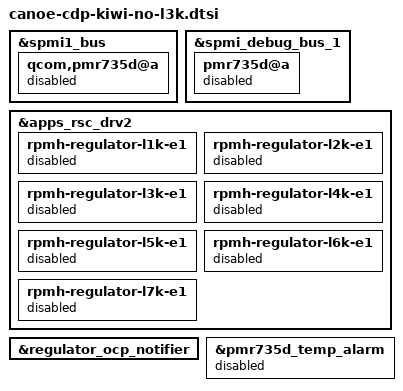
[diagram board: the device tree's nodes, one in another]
// SPDX-License-Identifier: BSD-3-Clause
/*
 * Copyright (c) Qualcomm Technologies, Inc. and/or its subsidiaries.
 */

#include "canoe-cdp.dtsi"

&spmi1_bus {
	qcom,pmr735d@a {
		status = "disabled";
	};
};

&spmi_debug_bus_1 {
	pmr735d@a {
		status = "disabled";
	};
};

&apps_rsc_drv2 {
	rpmh-regulator-l1k-e1 {
		status = "disabled";
	};

	rpmh-regulator-l2k-e1 {
		status = "disabled";
	};

	rpmh-regulator-l3k-e1 {
		status = "disabled";
	};

	rpmh-regulator-l4k-e1 {
		status = "disabled";
	};

	rpmh-regulator-l5k-e1 {
		status = "disabled";
	};

	rpmh-regulator-l6k-e1 {
		status = "disabled";
	};

	rpmh-regulator-l7k-e1 {
		status = "disabled";
	};
};

&regulator_ocp_notifier {
	/delete-property/ periph-ac1-supply; /* L1K */
	/delete-property/ periph-ac2-supply; /* L2K */
	/delete-property/ periph-ac3-supply; /* L3K */
	/delete-property/ periph-ac4-supply; /* L4K */
	/delete-property/ periph-ac5-supply; /* L5K */
	/delete-property/ periph-ac6-supply; /* L6K */
	/delete-property/ periph-ac7-supply; /* L7K */
};

&pmr735d_temp_alarm {
	status = "disabled";
};
